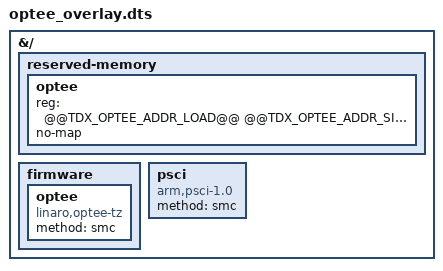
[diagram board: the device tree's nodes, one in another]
// SPDX-License-Identifier: GPL-2.0-or-later OR MIT
/*
 * Copyright 2025 Toradex
 */

/dts-v1/;
/plugin/;

&{/} {
	reserved-memory {
		#address-cells = <1>;
		#size-cells = <1>;
		ranges;

		optee {
			reg = <@@TDX_OPTEE_ADDR_LOAD@@ @@TDX_OPTEE_ADDR_SIZE@@>;
			no-map;
		};
	};

	firmware {
		optee {
			compatible = "linaro,optee-tz";
			method = "smc";
		};
	};

	psci {
		compatible = "arm,psci-1.0";
		method = "smc";
	};
};
